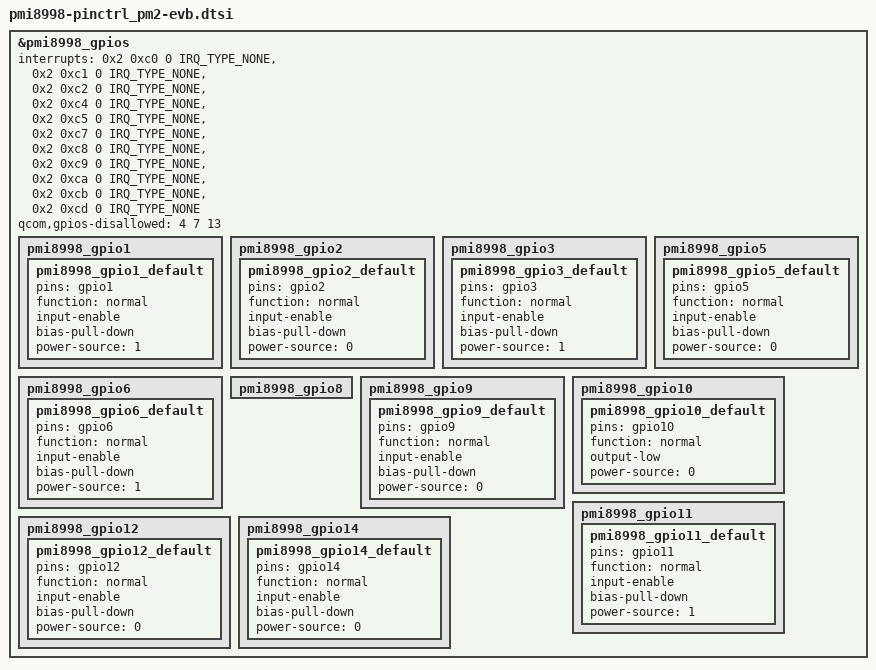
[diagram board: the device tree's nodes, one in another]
&pmi8998_gpios {
	interrupts = <0x2 0xc0 0 IRQ_TYPE_NONE>,
			<0x2 0xc1 0 IRQ_TYPE_NONE>,
			<0x2 0xc2 0 IRQ_TYPE_NONE>,
			<0x2 0xc4 0 IRQ_TYPE_NONE>,
			<0x2 0xc5 0 IRQ_TYPE_NONE>,
			<0x2 0xc7 0 IRQ_TYPE_NONE>,
			<0x2 0xc8 0 IRQ_TYPE_NONE>,
			<0x2 0xc9 0 IRQ_TYPE_NONE>,
			<0x2 0xca 0 IRQ_TYPE_NONE>,
			<0x2 0xcb 0 IRQ_TYPE_NONE>,
			<0x2 0xcd 0 IRQ_TYPE_NONE>;
	interrupt-names = "pmi8998_gpio1", "pmi8998_gpio2",
			"pmi8998_gpio3", "pmi8998_gpio5",
			"pmi8998_gpio6", "pmi8998_gpio8",
			"pmi8998_gpio9", "pmi8998_gpio10",
			"pmi8998_gpio11", "pmi8998_gpio12",
			"pmi8998_gpio14";
	qcom,gpios-disallowed = <4 7 13>;

	pmi8998_gpio1 { /* No Use */
		pmi8998_gpio1_default: pmi8998_gpio1_default {
			pins = "gpio1";
			function = "normal";
			input-enable;
			bias-pull-down;
			power-source = <1>;
		};
	};

	pmi8998_gpio2 { /* No Use */
		pmi8998_gpio2_default: pmi8998_gpio2_default {
			pins = "gpio2";
			function = "normal";
			input-enable;
			bias-pull-down;
			power-source = <0>;
		};
	};

	pmi8998_gpio3 { /* No Use */
		pmi8998_gpio3_default: pmi8998_gpio3_default {
			pins = "gpio3";
			function = "normal";
			input-enable;
			bias-pull-down;
			power-source = <1>;
		};
	};

	/*pmi8998_gpio4 { // TYPEC_UUSB_SEL - disallow config
	}*/

	pmi8998_gpio5 { /* No Use */
		pmi8998_gpio5_default: pmi8998_gpio5_default {
			pins = "gpio5";
			function = "normal";
			input-enable;
			bias-pull-down;
			power-source = <0>;
		};
	};

	pmi8998_gpio6 { /* No Use */
		pmi8998_gpio6_default: pmi8998_gpio6_default {
			pins = "gpio6";
			function = "normal";
			input-enable;
			bias-pull-down;
			power-source = <1>;
		};
	};

	/*pmi8998_gpio7 { // LCM_SEL - disallow config
	};*/

	pmi8998_gpio8 { /* US_EURO_SEL */
	};

	pmi8998_gpio9 { /* No Use */
		pmi8998_gpio9_default: pmi8998_gpio9_default {
			pins = "gpio9";
			function = "normal";
			input-enable;
			bias-pull-down;
			power-source = <0>;
		};
	};

	pmi8998_gpio10 { /* 5V_BOOST_EN */
		pmi8998_gpio10_default: pmi8998_gpio10_default {
			pins = "gpio10";
			function = "normal";
			output-low;
			power-source = <0>;
		};
	};

	pmi8998_gpio11 { /* No Use */
		pmi8998_gpio11_default: pmi8998_gpio11_default {
			pins = "gpio11";
			function = "normal";
			input-enable;
			bias-pull-down;
			power-source = <1>;
		};
	};

	pmi8998_gpio12 { /* No Use */
		pmi8998_gpio12_default: pmi8998_gpio12_default {
			pins = "gpio12";
			function = "normal";
			input-enable;
			bias-pull-down;
			power-source = <0>;
		};
	};

	/*pmi8998_gpio13 { // SPMI_I2C_SEL - disallow config
	};*/

	pmi8998_gpio14 { /* No Use */
		pmi8998_gpio14_default: pmi8998_gpio14_default {
			pins = "gpio14";
			function = "normal";
			input-enable;
			bias-pull-down;
			power-source = <0>;
		};
	};
};
